# STM32U345 register map
File version: 1.0
CPU: CM33 r0p1, little endian, MPU, FPU, 4 interrupt priority bits
Registers are 32-bit, read-write, reset 0x0 unless marked. A register's access mark holds for its fields unless they carry their own. Offsets are from the block's base; [hi:lo] are bit positions; {n}, {i} and the like mark numbered series; 'fields as' and 'values as' point back to an identical list.

## EXTI — EXTI register block
Base 0x40032000
Same registers: EXTI_S 0x50032000
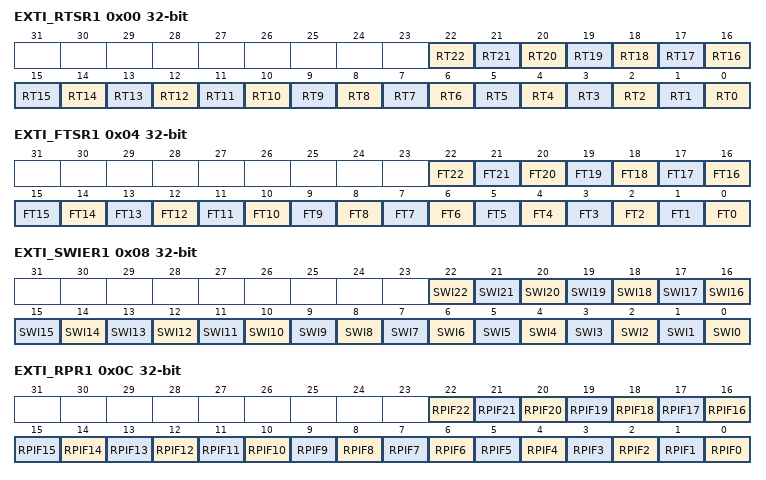
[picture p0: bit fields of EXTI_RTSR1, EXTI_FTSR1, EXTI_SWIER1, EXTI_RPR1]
0x00 EXTI_RTSR1 — This register contains only bits for configurable events.
  [all] fields
    0=Rising trigger disabled (for event and interrupt) for input line; 1=Rising trigger enabled (for event and interrupt) for input line
  [n] RT{n} (n=0..22) — Rising trigger event configuration bit of configurable event input i When EXTI_SECCFGR.SECi is disabled, RTx can be accessed with nonsecure and secure access. When EXTI_SECCFGR.SECi is enabled, RTi can only be accessed with secure access. Nonsecure write to this bit i is discarded and nonsecure read returns 0. When EXTI_PRIVCFGR.PRIVi is disabled, RTi can be accessed with unprivileged and privileged access. When EXTI_PRIVCFGR.PRIVi is enabled, RTi can only be accessed with privileged access. Unprivileged write to this bit i is discarded. Unprivileged read returns 0.
0x04 EXTI_FTSR1 — This register contains only bits for configurable events.
  [all] fields
    0=Falling trigger disabled (for event and interrupt) for input line; 1=Falling trigger enabled (for event and interrupt) for input line
  [n] FT{n} (n=0..22) — Falling trigger event configuration bit of configurable event input i When EXTI_SECCFGR.SECi is disabled, FTi can be accessed with nonsecure and secure access. When EXTI_SECCFGR.SECi is enabled, FTi can only be accessed with secure access. Nonsecure write to this FTi is discarded. Nonsecure read returns 0. When EXTI_PRIVCFGR.PRIVi is disabled, FTi can be accessed with unprivileged and privileged access. When EXTI_PRIVCFGR.PRIVi is enabled, FTi can only be accessed with privileged access. Unprivileged write to this FTi is discarded, unprivileged read returns 0.
0x08 EXTI_SWIER1 — This register contains only bits for configurable events.
  [all] fields
    0=Writing 0 has no effect; 1=Writing 1 triggers a rising edge event on event i. This bit is auto cleared by hardware.
  [n] SWI{n} (n=0..22) — Software interrupt on event i When EXTI_SECCFGR.SECi is disabled, SWIi can be accessed with nonsecure and secure access. When EXTI_SECCFGR.SECi is enabled, SWIi can only be accessed with secure access. Nonsecure write to this SWIi is discarded. Nonsecure read returns 0. When EXTI_PRIVCFGR.PRIVi is disabled, SWIi can be accessed with unprivileged and privileged access. When EXTI_PRIVCFGR.PRIVi is enabled, SWIi can only be accessed with privileged access. Unprivileged write to this SWIi is discarded, unprivileged read returns 0. A software interrupt is generated independent from the setting in EXTI_RTSR and EXTI_FTSR. It always returns 0 when read.
0x0C EXTI_RPR1 — This register contains only bits for configurable events.
  [all] fields
    0=No rising edge trigger request occurred; 1=Rising edge trigger request occurred
  [n] RPIF{n} (n=0..22) — Configurable event input i rising edge pending bit When EXTI_SECCFGR.SECi is disabled, RPIFi can be accessed with nonsecure and secure access. When EXTI_SECCFGR.SECi is enabled, RPIFi can only be accessed with secure access. Nonsecure write to this RPIFi is discarded. Nonsecure read returns 0. When EXTI_PRIVCFGR.PRIVi is disabled, RPIFi can be accessed with unprivileged and privileged access. When EXTI_PRIVCFGR.PRIVi is enabled, RPIFi can only be accessed with privileged access. Unprivileged write to this RPIFi is discarded, unprivileged read returns 0. This bit is set when the rising edge event or an EXTI_SWIER software trigger arrives on the configurable event line. This bit is cleared by writing 1 to it.
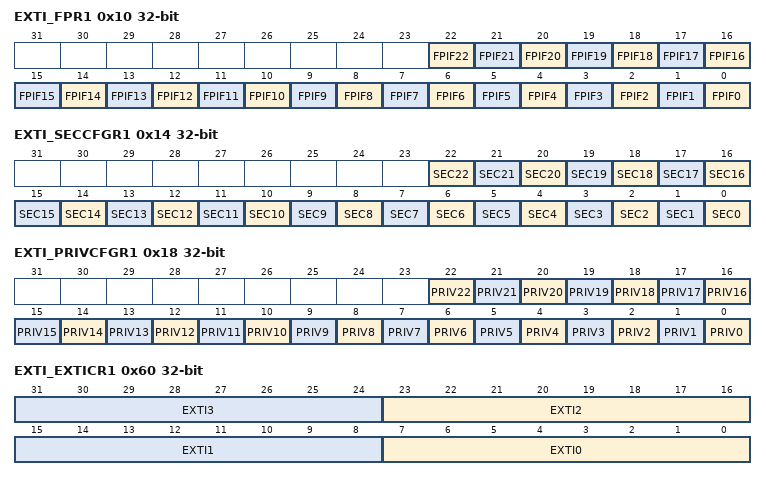
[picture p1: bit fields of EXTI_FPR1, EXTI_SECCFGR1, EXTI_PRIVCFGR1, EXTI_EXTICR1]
0x10 EXTI_FPR1 — This register contains only bits for configurable events.
  [all] fields
    0=No falling edge trigger request occurred; 1=Falling edge trigger request occurred
  [n] FPIF{n} (n=0..22) — configurable event inputs i falling edge pending bit When EXTI_SECCFGR.SECi is disabled, FPIFi can be accessed with nonsecure and secure access. When EXTI_SECCFGR.SECi is enabled, FPIFi can only be accessed with secure access. Nonsecure write to this FPIFi is discarded, nonsecure read returns 0. When EXTI_PRIVCFGR.PRIVi is disabled, FPIFi can be accessed with unprivileged and privileged access. When EXTI_PRIVCFGR.PRIVi is enabled, FPIFi can only be accessed with privileged access. Unprivileged write to this FPIFi is discarded, unprivileged read returns 0. This bit is set when the falling edge event arrives on the configurable event line. This bit is cleared by writing 1 to it.
0x14 EXTI_SECCFGR1 — This register provides write access security. A nonsecure write access is ignored and causes the generation of an illegal access event. A nonsecure read returns the register data. This register contains only bits for security capable input events.
  [all] fields
    0=Event security disabled (nonsecure); 1=Event security enabled (secure)
  [n] SEC{n} (n=0..22) — Security enable on event input i When EXTI_PRIVCFGR.PRIVi is disabled, SECi can be accessed with privileged and unprivileged access. When EXTI_PRIVCFGR.PRIVi is enabled, SECi can only be written with privileged access. Unprivileged write to this SECi is discarded.
0x18 EXTI_PRIVCFGR1 — This register provides privileged write access protection. An unprivileged read returns the register data. This register contains only bits for security capable input events.
  [all] fields
    0=Event privilege disabled (unprivileged); 1=Event privilege enabled (privileged)
  [n] PRIV{n} (n=0..22) — Security enable on event input i When EXTI_SECCFGR.SECi is disabled, PRIVi can be accessed with secure and nonsecure access. When EXTI_SECCFGR.SECi is enabled, PRIVi can only be written with secure access. Nonsecure write to this PRIVi is discarded.
0x60 EXTI_EXTICR1 — EXTI external interrupt selection register
  [8n+7:8n] EXTI{n} (n=0..3) — EXTI{n} GPIO port selection These bits are written by software to select the source input for EXTI{n} external interrupt. When EXTI_SECCFGR.SEC{n} is disabled, this bit field can be accessed with nonsecure and secure access. When EXTI_SECCFGR.SEC{n} is enabled, this bit field can only be accessed with secure access. Nonsecure write is discarded. Nonsecure read returns 0. When EXTI_PRIVCFGR.PRIV{n} is disabled, this bit field can be accessed with privileged and unprivileged access. When EXTI_PRIVCFGR.PRIV{n} is enabled, this bit field can only be accessed with privileged access. Unprivileged write to this bit is discarded. Others: Reserved Note: Port F is only available in STM32U3B5/3C5.
    0=PA[{n}] pin; 1=PB[{n}] pin; 2=PC[{n}] pin; 3=PD[{n}] pin; 4=PE[{n}] pin; 5=PF[{n}] pin; 6=PG[{n}] pin; 7=PH[{n}] pin
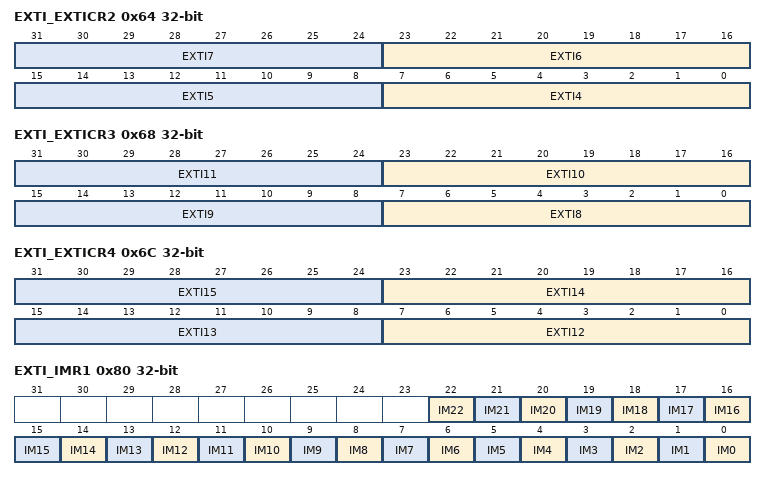
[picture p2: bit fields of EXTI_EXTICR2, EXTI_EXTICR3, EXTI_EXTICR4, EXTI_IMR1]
0x64 EXTI_EXTICR2 — EXTI external interrupt selection register
  [8n-25:8n-32] EXTI{n} (n=4..7) — EXTI{n} GPIO port selection These bits are written by software to select the source input for EXTI{n} external interrupt. When EXTI_SECCFGR.SEC{n} is disabled, this bit field can be accessed with nonsecure and secure access. When EXTI_SECCFGR.SEC{n} is enabled, this bit field can only be accessed with secure access. Nonsecure write is discarded. Nonsecure read returns 0. When EXTI_PRIVCFGR.PRIV{n} is disabled, this bit field can be accessed with privileged and unprivileged access. When EXTI_PRIVCFGR.PRIV{n} is enabled, this bit field can only be accessed with privileged access. Unprivileged write to this bit is discarded. Others: Reserved Note: Port F is only available in STM32U3B5/3C5.
    values as EXTI_EXTICR1.EXTI0
0x68 EXTI_EXTICR3 — EXTI external interrupt selection register
  [8n-57:8n-64] EXTI{n} (n=8..11) — EXTI{n} GPIO port selection These bits are written by software to select the source input for EXTI{n} external interrupt. When EXTI_SECCFGR.SEC{n} is disabled, this bit field can be accessed with nonsecure and secure access. When EXTI_SECCFGR.SEC{n} is enabled, this bit field can only be accessed with secure access. Nonsecure write is discarded. Nonsecure read returns 0. When EXTI_PRIVCFGR.PRIV{n} is disabled, this bit field can be accessed with privileged and unprivileged access. When EXTI_PRIVCFGR.PRIV{n} is enabled, this bit field can only be accessed with privileged access. Unprivileged write to this bit is discarded. Others: Reserved Note: Port F is only available in STM32U3B5/3C5.
    values as EXTI_EXTICR1.EXTI0
0x6C EXTI_EXTICR4 — EXTI external interrupt selection register
  [8n-89:8n-96] EXTI{n} (n=12..15) — EXTI{n} GPIO port selection These bits are written by software to select the source input for EXTI{n} external interrupt. When EXTI_SECCFGR.SEC{n} is disabled, this bit field can be accessed with nonsecure and secure access. When EXTI_SECCFGR.SEC{n} is enabled, this bit field can only be accessed with secure access. Nonsecure write is discarded. Nonsecure read returns 0. When EXTI_PRIVCFGR.PRIV{n} is disabled, this bit field can be accessed with privileged and unprivileged access. When EXTI_PRIVCFGR.PRIV{n} is enabled, this bit field can only be accessed with privileged access. Unprivileged write to this bit is discarded. Others: Reserved Note: Port F is only available in STM32U3B5/3C5.
    values as EXTI_EXTICR1.EXTI0
0x70 EXTI_LOCKR — This register provides write access security: a nonsecure write access is ignored, a read access returns zero data, and both generates an illegal access event.
  [0] LOCK — Global security and privilege configuration registers (EXTI_SECCFGR and EXTI_PRIVCFGR) lock This bit is written once after reset.
    0=Security and privilege configuration open, can be modified; 1=Security and privilege configuration locked, can no longer be modified
0x80 EXTI_IMR1 — This register contains bits for configurable events.
  [all] fields
    0=Wake-up with interrupt request from input event i is masked; 1=Wake-up with interrupt request from input event i is unmasked
  [n] IM{n} (n=0..22) — CPU wake-up with interrupt mask on event input i When EXTI_SECCFGR.SECi is disabled, IMi can be accessed with nonsecure and secure access. When EXTI_SECCFGR.SECi is enabled, IMi can only be accessed with secure access. Nonsecure write to this bit is discarded. Nonsecure read returns 0. When EXTI_PRIVCFGR.PRIVi is disabled, IMi can be accessed with privileged and unprivileged access. When EXTI_PRIVCFGR.PRIVi is enabled, IMi can only be accessed with privileged access. Unprivileged write to this bit is discarded.
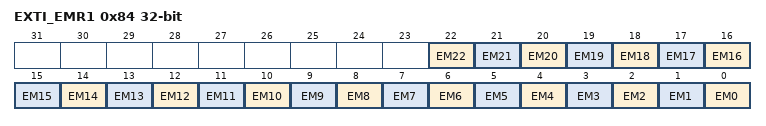
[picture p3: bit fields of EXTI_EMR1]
0x84 EXTI_EMR1
  [all] fields
    0=Wake-up with event generation from line i is masked; 1=Wake-up with event generation from line i is unmasked
  [n] EM{n} (n=0..22) — CPU wake-up with event generation mask on event input i When EXTI_SECCFGR.SECi is disabled, EMi can be accessed with nonsecure and secure access. When EXTI_SECCFGR.SECi is enabled, EMi can only be accessed with secure access. Nonsecure write to this EMi is discarded. Nonsecure read returns 0. When EXTI_PRIVCFGR.PRIVi is disabled, EMi can be accessed with privileged and unprivileged access. When EXTI_PRIVCFGR.PRIVi is enabled, EMi can only be accessed with privileged access. Unprivileged write to this bit is discarded.
